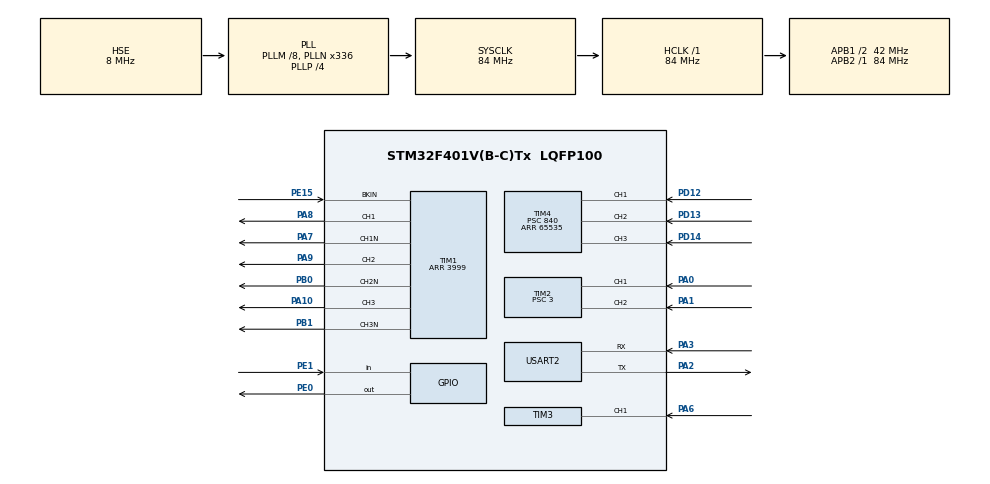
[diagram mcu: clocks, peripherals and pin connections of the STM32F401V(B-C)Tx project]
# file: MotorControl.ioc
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FREERTOS.Tasks01=defaultTask,0,128,StartDefaultTask,Default,NULL
Mcu.Family=STM32F4
Mcu.Name=STM32F401V(B-C)Tx
Mcu.Package=LQFP100
NVIC.PriorityGroup=NVIC_PRIORITYGROUP_4
NVIC.TIM1_BRK_TIM9_IRQn=true\:5\:0\:false\:false\:true\:true
NVIC.TIM4_IRQn=true\:5\:0\:false\:false\:true\:true
NVIC.TIM5_IRQn=true\:0\:0\:false\:false\:true\:false
NVIC.TimeBase=TIM5_IRQn
NVIC.TimeBaseIP=TIM5
PA0-WKUP.Signal=S_TIM2_CH1_ETR
PA1.Signal=S_TIM2_CH2
PA10.GPIO_ModeDefaultPP=GPIO_MODE_AF_PP
PA10.GPIO_PuPd=GPIO_NOPULL
PA10.GPIO_Speed=GPIO_SPEED_FREQ_VERY_HIGH
PA10.Signal=S_TIM1_CH3
PA2.GPIO_Speed=GPIO_SPEED_FREQ_HIGH
PA2.Mode=Asynchronous
PA2.Signal=USART2_TX
PA3.GPIO_Speed=GPIO_SPEED_FREQ_HIGH
PA3.Mode=Asynchronous
PA3.Signal=USART2_RX
PA6.Signal=S_TIM3_CH1
PA7.GPIO_ModeDefaultPP=GPIO_MODE_AF_PP
PA7.GPIO_PuPd=GPIO_NOPULL
PA7.GPIO_Speed=GPIO_SPEED_FREQ_VERY_HIGH
PA7.Mode=PWM Generation1 CH1 CH1N
PA7.Signal=TIM1_CH1N
PA8.GPIO_ModeDefaultPP=GPIO_MODE_AF_PP
PA8.GPIO_PuPd=GPIO_NOPULL
PA8.GPIO_Speed=GPIO_SPEED_FREQ_VERY_HIGH
PA8.Signal=S_TIM1_CH1
PA9.GPIO_ModeDefaultPP=GPIO_MODE_AF_PP
PA9.GPIO_PuPd=GPIO_NOPULL
PA9.GPIO_Speed=GPIO_SPEED_FREQ_VERY_HIGH
PA9.Signal=S_TIM1_CH2
PB0.GPIO_ModeDefaultPP=GPIO_MODE_AF_PP
PB0.GPIO_PuPd=GPIO_NOPULL
PB0.GPIO_Speed=GPIO_SPEED_FREQ_VERY_HIGH
PB0.Mode=PWM Generation2 CH2 CH2N
PB0.Signal=TIM1_CH2N
PB1.GPIO_ModeDefaultPP=GPIO_MODE_AF_PP
PB1.GPIO_PuPd=GPIO_NOPULL
PB1.GPIO_Speed=GPIO_SPEED_FREQ_VERY_HIGH
PB1.Mode=PWM Generation3 CH3 CH3N
PB1.Signal=TIM1_CH3N
PD12.Signal=S_TIM4_CH1
PD13.Signal=S_TIM4_CH2
PD14.Signal=S_TIM4_CH3
PE0.GPIO_Speed=GPIO_SPEED_FREQ_HIGH
PE0.Signal=GPIO_Output
PE1.Signal=GPIO_Input
PE15.Mode=Activate-Break-Input
PE15.Signal=TIM1_BKIN
PH0\ -\ OSC_IN.Mode=HSE-External-Clock-Source
PH0\ -\ OSC_IN.Signal=RCC_OSC_IN
PH1\ -\ OSC_OUT.Mode=HSE-External-Clock-Source
PH1\ -\ OSC_OUT.Signal=RCC_OSC_OUT
ProjectManager.HeapSize=0x200
ProjectManager.StackSize=0x400
ProjectManager.TargetToolchain=EWARM
RCC.48MHZClocksFreq_Value=84000000
RCC.AHBFreq_Value=84000000
RCC.APB1CLKDivider=RCC_HCLK_DIV2
RCC.APB1Freq_Value=42000000
RCC.APB1TimFreq_Value=84000000
RCC.APB2Freq_Value=84000000
RCC.APB2TimFreq_Value=84000000
RCC.CortexFreq_Value=84000000
RCC.EnbaleCSS=true
RCC.HCLKFreq_Value=84000000
RCC.HSE_VALUE=8000000
RCC.HSI_VALUE=16000000
RCC.LSE_VALUE=32768
RCC.PLLM=8
RCC.PLLN=336
RCC.PLLP=RCC_PLLP_DIV4
RCC.PLLSourceVirtual=RCC_PLLSOURCE_HSE
RCC.SYSCLKFreq_VALUE=84000000
RCC.SYSCLKSource=RCC_SYSCLKSOURCE_PLLCLK
RCC.VCOOutputFreq_Value=336000000
SH.S_TIM1_CH1.0=TIM1_CH1,PWM Generation1 CH1 CH1N
SH.S_TIM1_CH2.0=TIM1_CH2,PWM Generation2 CH2 CH2N
SH.S_TIM1_CH3.0=TIM1_CH3,PWM Generation3 CH3 CH3N
SH.S_TIM2_CH1_ETR.0=TIM2_CH1,Encoder_Interface
SH.S_TIM2_CH2.0=TIM2_CH2,Encoder_Interface
SH.S_TIM3_CH1.0=TIM3_CH1,TriggerSource_TI1FP1
SH.S_TIM4_CH1.0=TIM4_CH1,Xored_Inputs_Hall_Sensor_Interface
SH.S_TIM4_CH2.0=TIM4_CH2,Xored_Inputs_Hall_Sensor_Interface
SH.S_TIM4_CH3.0=TIM4_CH3,Xored_Inputs_Hall_Sensor_Interface
TIM1.AutomaticOutput=TIM_AUTOMATICOUTPUT_ENABLE
TIM1.BreakPolarity=TIM_BREAKPOLARITY_LOW
TIM1.BreakState=TIM_BREAK_ENABLE
TIM1.Channel-PWM\ Generation1\ CH1\ CH1N=TIM_CHANNEL_1
TIM1.Channel-PWM\ Generation2\ CH2\ CH2N=TIM_CHANNEL_2
TIM1.Channel-PWM\ Generation3\ CH3\ CH3N=TIM_CHANNEL_3
TIM1.DeadTime=84
TIM1.LockLevel=TIM_LOCKLEVEL_OFF
TIM1.OCIdleState_1=TIM_OCIDLESTATE_RESET
TIM1.OCIdleState_2=TIM_OCIDLESTATE_RESET
TIM1.OCIdleState_3=TIM_OCIDLESTATE_RESET
TIM1.OCMode_PWM-PWM\ Generation1\ CH1\ CH1N=TIM_OCMODE_PWM1
TIM1.OCMode_PWM-PWM\ Generation2\ CH2\ CH2N=TIM_OCMODE_PWM1
TIM1.OCMode_PWM-PWM\ Generation3\ CH3\ CH3N=TIM_OCMODE_PWM1
TIM1.OCNIdleState_1=TIM_OCNIDLESTATE_SET
TIM1.OCNIdleState_2=TIM_OCNIDLESTATE_SET
TIM1.OCNIdleState_3=TIM_OCNIDLESTATE_SET
TIM1.OCNPolarity_1=TIM_OCNPOLARITY_HIGH
TIM1.OCNPolarity_2=TIM_OCNPOLARITY_HIGH
TIM1.OCNPolarity_3=TIM_OCNPOLARITY_HIGH
TIM1.OCPolarity_1=TIM_OCPOLARITY_HIGH
TIM1.OCPolarity_2=TIM_OCPOLARITY_HIGH
TIM1.OCPolarity_3=TIM_OCPOLARITY_HIGH
TIM1.OffStateIDLEMode=TIM_OSSI_ENABLE
TIM1.OffStateRunMode=TIM_OSSR_ENABLE
TIM1.Period=3999
TIM1.Pulse-PWM\ Generation1\ CH1\ CH1N=399
TIM1.Pulse-PWM\ Generation2\ CH2\ CH2N=399
TIM1.Pulse-PWM\ Generation3\ CH3\ CH3N=399
TIM1.TIM_MasterOutputTrigger=TIM_TRGO_RESET
TIM1.TIM_MasterSlaveMode=TIM_MASTERSLAVEMODE_DISABLE
TIM2.EncoderMode=TIM_ENCODERMODE_TI12
TIM2.Period=4294967295
TIM2.Prescaler=3
TIM3.Period=65535
TIM4.Commutation_Delay=1
TIM4.Period=65535
TIM4.Prescaler=840
USART2.VirtualMode=VM_ASYNC
VP_FREERTOS_VS_ENABLE.Mode=Enabled
VP_SYS_VS_tim5.Mode=TIM5
VP_TIM1_VS_ClockSourceITR.Mode=TriggerSource_ITR3
VP_TIM1_VS_ControllerModeTrigger.Mode=Trigger Mode
VP_TIM3_VS_ControllerModeClock.Mode=Clock Mode
board=MotorControl

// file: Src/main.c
/**
  ******************************************************************************
  * File Name          : main.c
  * Description        : Main program body
  ******************************************************************************
  * This notice applies to any and all portions of this file
  * that are not between comment pairs USER CODE BEGIN and
  * USER CODE END. Other portions of this file, whether
  * inserted by the user or by software development tools
  * are owned by their respective copyright owners.
  *
  * Copyright (c) 2017 STMicroelectronics International N.V.
  * All rights reserved.
  *
  * Redistribution and use in source and binary forms, with or without
  * modification, are permitted, provided that the following conditions are met:
  *
  * 1. Redistribution of source code must retain the above copyright notice,
  *    this list of conditions and the following disclaimer.
  * 2. Redistributions in binary form must reproduce the above copyright notice,
  *    this list of conditions and the following disclaimer in the documentation
  *    and/or other materials provided with the distribution.
  * 3. Neither the name of STMicroelectronics nor the names of other
  *    contributors to this software may be used to endorse or promote products
  *    derived from this software without specific written permission.
  * 4. This software, including modifications and/or derivative works of this
  *    software, must execute solely and exclusively on microcontroller or
  *    microprocessor devices manufactured by or for STMicroelectronics.
  * 5. Redistribution and use of this software other than as permitted under
  *    this license is void and will automatically terminate your rights under
  *    this license.
  *
  * THIS SOFTWARE IS PROVIDED BY STMICROELECTRONICS AND CONTRIBUTORS "AS IS"
  * AND ANY EXPRESS, IMPLIED OR STATUTORY WARRANTIES, INCLUDING, BUT NOT
  * LIMITED TO, THE IMPLIED WARRANTIES OF MERCHANTABILITY, FITNESS FOR A
  * PARTICULAR PURPOSE AND NON-INFRINGEMENT OF THIRD PARTY INTELLECTUAL PROPERTY
  * RIGHTS ARE DISCLAIMED TO THE FULLEST EXTENT PERMITTED BY LAW. IN NO EVENT
  * SHALL STMICROELECTRONICS OR CONTRIBUTORS BE LIABLE FOR ANY DIRECT, INDIRECT,
  * INCIDENTAL, SPECIAL, EXEMPLARY, OR CONSEQUENTIAL DAMAGES (INCLUDING, BUT NOT
  * LIMITED TO, PROCUREMENT OF SUBSTITUTE GOODS OR SERVICES; LOSS OF USE, DATA,
  * OR PROFITS; OR BUSINESS INTERRUPTION) HOWEVER CAUSED AND ON ANY THEORY OF
  * LIABILITY, WHETHER IN CONTRACT, STRICT LIABILITY, OR TORT (INCLUDING
  * NEGLIGENCE OR OTHERWISE) ARISING IN ANY WAY OUT OF THE USE OF THIS SOFTWARE,
  * EVEN IF ADVISED OF THE POSSIBILITY OF SUCH DAMAGE.
  *
  ******************************************************************************
  */
#include "main.h"
#include "stm32f4xx_hal.h"
#include "cmsis_os.h"
#include "tim.h"
#include "usart.h"
#include "gpio.h"

void SystemClock_Config(void);
void MX_FREERTOS_Init(void);

/* USER CODE BEGIN PFP */
/* Private function prototypes -----------------------------------------------*/

/* USER CODE END PFP */

int main(void)
{

  /* MCU Configuration----------------------------------------------------------*/

  /* Reset of all peripherals, Initializes the Flash interface and the Systick. */
  HAL_Init();

  /* Configure the system clock */
  SystemClock_Config();

  /* Initialize all configured peripherals */
  MX_GPIO_Init();
  MX_USART2_UART_Init();
  MX_TIM3_Init();
  MX_TIM2_Init();
  MX_TIM1_Init();
  MX_TIM4_Init();

  /* USER CODE BEGIN 2 */
  printf("<<<<<<<<<<<<Motion Transmission Test>>>>>>>>>>>>>\r\n");

  /* Enable TIM1 interrupt */
  HAL_TIMEx_ConfigCommutationEvent(&htim1, TIM_TS_ITR3, TIM_COMMUTATION_TRGI);

  /* Enable TIM4 OC2REF interrupt for commutation */
  HAL_TIM_OC_Start_IT(&htim4, TIM_CHANNEL_2);

  /* Enable TIM4 BREAK interrupt */
  __HAL_TIM_ENABLE_IT(&htim1, TIM_IT_BREAK);

  /* Enable Encoder Counter */
  HAL_TIM_Encoder_Start(&htim2, TIM_CHANNEL_1 | TIM_CHANNEL_2);

  /* USER CODE END 2 */

  /* Call init function for freertos objects (in freertos.c) */
  MX_FREERTOS_Init();

  /* Start scheduler */
  osKernelStart();

  /* We should never get here as control is now taken by the scheduler */

  /* Infinite loop */
  while (1)
  {

  }

}

/** System Clock Configuration
*/
void SystemClock_Config(void)
{

  RCC_OscInitTypeDef RCC_OscInitStruct;
  RCC_ClkInitTypeDef RCC_ClkInitStruct;

    /**Configure the main internal regulator output voltage
    */
  __HAL_RCC_PWR_CLK_ENABLE();

  __HAL_PWR_VOLTAGESCALING_CONFIG(PWR_REGULATOR_VOLTAGE_SCALE2);

    /**Initializes the CPU, AHB and APB busses clocks
    */
  RCC_OscInitStruct.OscillatorType = RCC_OSCILLATORTYPE_HSE;
  RCC_OscInitStruct.HSEState = RCC_HSE_BYPASS;
  RCC_OscInitStruct.PLL.PLLState = RCC_PLL_ON;
  RCC_OscInitStruct.PLL.PLLSource = RCC_PLLSOURCE_HSE;
  RCC_OscInitStruct.PLL.PLLM = 8;
  RCC_OscInitStruct.PLL.PLLN = 336;
  RCC_OscInitStruct.PLL.PLLP = RCC_PLLP_DIV4;
  RCC_OscInitStruct.PLL.PLLQ = 4;
  if (HAL_RCC_OscConfig(&RCC_OscInitStruct) != HAL_OK)
  {
    _Error_Handler(__FILE__, __LINE__);
  }

    /**Initializes the CPU, AHB and APB busses clocks
    */
  RCC_ClkInitStruct.ClockType = RCC_CLOCKTYPE_HCLK|RCC_CLOCKTYPE_SYSCLK
                              |RCC_CLOCKTYPE_PCLK1|RCC_CLOCKTYPE_PCLK2;
  RCC_ClkInitStruct.SYSCLKSource = RCC_SYSCLKSOURCE_PLLCLK;
  RCC_ClkInitStruct.AHBCLKDivider = RCC_SYSCLK_DIV1;
  RCC_ClkInitStruct.APB1CLKDivider = RCC_HCLK_DIV2;
  RCC_ClkInitStruct.APB2CLKDivider = RCC_HCLK_DIV1;

  if (HAL_RCC_ClockConfig(&RCC_ClkInitStruct, FLASH_LATENCY_2) != HAL_OK)
  {
    _Error_Handler(__FILE__, __LINE__);
  }

    /**Enables the Clock Security System
    */
  HAL_RCC_EnableCSS();

    /**Configure the Systick interrupt time
    */
  HAL_SYSTICK_Config(HAL_RCC_GetHCLKFreq()/1000);

    /**Configure the Systick
    */
  HAL_SYSTICK_CLKSourceConfig(SYSTICK_CLKSOURCE_HCLK);

  /* SysTick_IRQn interrupt configuration */
  HAL_NVIC_SetPriority(SysTick_IRQn, 15, 0);
}

void HAL_TIM_PeriodElapsedCallback(TIM_HandleTypeDef *htim)
{
  if (htim->Instance == TIM5) {
    HAL_IncTick();
  }
}

void _Error_Handler(char * file, int line)
{
  while(1)
  {
  }
}

/************************ (C) COPYRIGHT STMicroelectronics *****END OF FILE****/
